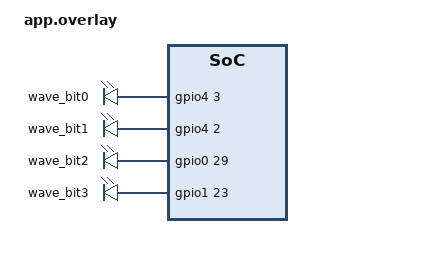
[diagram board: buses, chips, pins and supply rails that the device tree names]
// Waveform outputs on ARD_D0 - ARD_D3 
/ {
	waveform_pins {
		compatible = "gpio-leds";

		wave_bit0: wave_b0 { gpios = <&gpio4 3  GPIO_ACTIVE_HIGH>; };  // ARD_D0 
		wave_bit1: wave_b1 { gpios = <&gpio4 2  GPIO_ACTIVE_HIGH>; };  // ARD_D1 
		wave_bit2: wave_b2 { gpios = <&gpio0 29 GPIO_ACTIVE_HIGH>; };  // ARD_D2 
		wave_bit3: wave_b3 { gpios = <&gpio1 23 GPIO_ACTIVE_HIGH>; };  // ARD_D3 
	};
};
